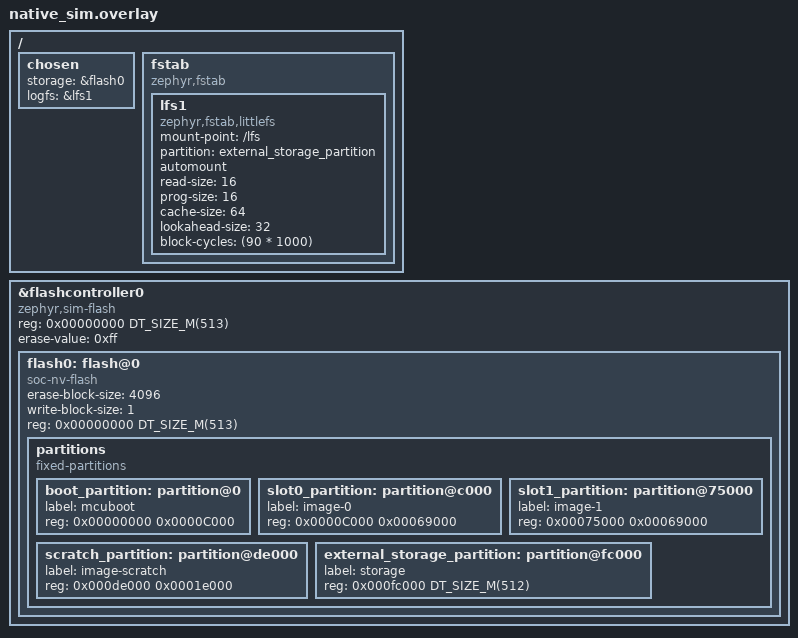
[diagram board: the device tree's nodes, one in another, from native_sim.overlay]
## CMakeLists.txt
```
cmake_minimum_required(VERSION 3.13.1)

set(FSW_ROOT ${CMAKE_CURRENT_SOURCE_DIR}/../../..)
include(${FSW_ROOT}/cmake/Snippets.cmake)
if (BOARD STREQUAL "native_sim")
    if (UNIX AND NOT APPLE)
        message(STATUS "Adding simulation configuration")
        AddSimSnippets()
    else ()
        message(FATAL_ERROR "Simulation is only supported on Linux systems")
    endif ()
endif ()

find_package(Zephyr REQUIRED HINTS $ENV{ZEPHYR_BASE})
project(tftp-server LANGUAGES C CXX)

FILE(GLOB sources src/*.c src/*.cpp)
target_include_directories(app PRIVATE include)
target_sources(app PRIVATE ${sources})
```

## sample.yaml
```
sample:
  description: tftp-server
  name: tftp-server
common:
  build_only: true
  platform_allow:
    - native_sim
tests:
  samples.tftp_server.default: {}
```

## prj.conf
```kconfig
# Copyright (c) 2024 RIT Launch Initiative
# SPDX-License-Identifier: Apache-2.0

# CPP
CONFIG_CPP=y
CONFIG_REQUIRES_FULL_LIBCPP=y
CONFIG_STD_CPP20=y

CONFIG_F_CORE=y
CONFIG_F_CORE_OS=y

# OS
CONFIG_POLL=y
CONFIG_MAIN_STACK_SIZE=4096
CONFIG_STACK_USAGE=y

CONFIG_TIMESLICING=y
CONFIG_TIMESLICE_SIZE=20
CONFIG_TIMESLICE_PRIORITY=0
CONFIG_THREAD_STACK_INFO=y

CONFIG_DYNAMIC_THREAD=y
# Max stack size for dynamic threads
CONFIG_DYNAMIC_THREAD_STACK_SIZE=512
# Number of threads in the dynamic thread pool
# (Zephyr wants 4 for some reason instead of 2)
CONFIG_DYNAMIC_THREAD_POOL_SIZE=4
CONFIG_SHELL=y
CONFIG_LOG=y

# F-Core
CONFIG_F_CORE=y
CONFIG_F_CORE_NET=y
CONFIG_F_CORE_OS=y

# Networking
CONFIG_NETWORKING=y
CONFIG_NET_NATIVE=y
CONFIG_NET_UDP=y
CONFIG_NET_SOCKETS=y
CONFIG_NET_IPV4=y
CONFIG_NET_L2_ETHERNET=y
CONFIG_NET_MAX_CONN=10
CONFIG_TEST_RANDOM_GENERATOR=y

# Filesystem
CONFIG_FILE_SYSTEM=y
CONFIG_FILE_SYSTEM_LITTLEFS=y
CONFIG_FS_LITTLEFS_FMP_DEV=y
CONFIG_FLASH=y
CONFIG_FLASH_MAP=y
CONFIG_FLASH_PAGE_LAYOUT=y
```

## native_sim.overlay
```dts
/ {
	chosen {
		storage = &flash0;
		logfs = &lfs1;
	};


	fstab {
		compatible = "zephyr,fstab";
		lfs1: lfs1 {
			compatible = "zephyr,fstab,littlefs";
			mount-point = "/lfs";
			partition = <&external_storage_partition>;
			automount;

			// the binding reccomends defaults for these
			read-size = <16>;
			prog-size = <16>;
			cache-size = <64>; // may need to grow for optimization
			lookahead-size = <32>;
			block-cycles = <(90 * 1000)>;
			// the datasheet gives 100K P-E cycles
			// NOTE: this seems to default to 512 for the mounted filesystem
			// anyway
		};
	};

};

&flashcontroller0 {
	status = "okay";
	compatible = "zephyr,sim-flash";
	reg = <0x00000000 DT_SIZE_M(513)>;

	#address-cells = <1>;
	#size-cells = <1>;
	erase-value = <0xff>;

	flash0: flash@0 {
		status = "okay";
		compatible = "soc-nv-flash";
		erase-block-size = <4096>;
		write-block-size = <1>;
		reg = <0x00000000 DT_SIZE_M(513)>; // builtin stuff + external flash simulation

		partitions {
			compatible = "fixed-partitions";
			#address-cells = <1>;
			#size-cells = <1>;

			boot_partition: partition@0 {
				label = "mcuboot";
				reg = <0x00000000 0x0000C000>;
			};
			slot0_partition: partition@c000 {
				label = "image-0";
				reg = <0x0000C000 0x00069000>;
			};
			slot1_partition: partition@75000 {
				label = "image-1";
				reg = <0x00075000 0x00069000>;
			};
			scratch_partition: partition@de000 {
				label = "image-scratch";
				reg = <0x000de000 0x0001e000>;
			};
			external_storage_partition: partition@fc000 {
				label = "storage";
				reg = <0x000fc000 DT_SIZE_M(512)>;
			};
		};
	};
};
```

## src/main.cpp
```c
/*
* Copyright (c) 2024 RIT Launch Initiative
 *
 * SPDX-License-Identifier: Apache-2.0
 */
#include <f_core/net/application/c_tftp_server_tenant.h>
#include <f_core/net/application/c_udp_broadcast_tenant.h>
#include <f_core/os/c_file.h>
#include <f_core/os/n_rtos.h>
#include <zephyr/fs/fs.h>
#include <zephyr/kernel.h>
#include <zephyr/logging/log.h>

LOG_MODULE_REGISTER(main, LOG_LEVEL_DBG);

int main() {
    CIPv4 ip("10.0.0.1");
    CTftpServerTenant *tftpServer = CTftpServerTenant::GetInstance(ip);
    tftpServer->Register();

    LOG_INF("Creating file");

    CFile file("/lfs/test.txt", FS_O_READ | FS_O_WRITE | FS_O_CREATE);
    if (file.GetInitStatus() < 0) {
        LOG_ERR("Error opening file");
        return -1;
    }

    int ret = file.Write("Hello, world!", 13);
    LOG_INF("Wrote to file %d", ret);

    while (true) {
        // TFTP Runs as a socket service now, so just keep the main thread alive
        k_msleep(1000);
    }

    return 0;
}
```

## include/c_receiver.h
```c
#ifndef HELLOTENANT_H
#define HELLOTENANT_H

#include "message.h"

// F-Core Includes
#include <f_core/messaging/c_message_port.h>
#include <f_core/os/c_tenant.h>

class CReceiver : public CTenant {
public:
    /**
     * Constructor
     * @param messagePort port to receive data from
     * @param completedPort port to receive data from
     * @param messageCountToReceive The number of messages to receive before stopping the RTOS
     */
    explicit CReceiver(CMessagePort<Message> &messagePort, CMessagePort<bool> &completedPort, int messageCountToReceive);

    /**
     * See parent docs
     */
    void Run() override;

private:
    using CBase = CTenant;

    CMessagePort<Message> &messagePort;
    CMessagePort<bool> &completedPort;

    int messageCountToReceive;
};

#endif //HELLOTENANT_H
```

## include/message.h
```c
#pragma once

struct Message {
    int count;
    char message[32];
};
```
